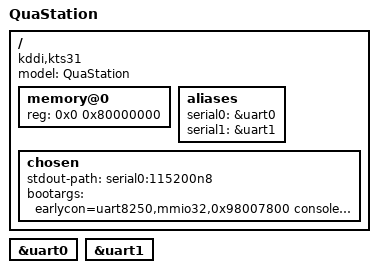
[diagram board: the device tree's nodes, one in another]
/*
 * Copyright (c) 2016-2017 Andreas Färber
 *
 * SPDX-License-Identifier: (GPL-2.0+ OR MIT)
 */

/dts-v1/;

#include "rtd1295.dtsi"

/ {
	compatible = "kddi,kts31", "realtek,rtd1295","Realtek,rtd1295";
	model = "QuaStation";

	memory@0 {
		device_type = "memory";
		reg = <0x0 0x80000000>;
	};

	aliases {
		serial0 = &uart0;
		serial1 = &uart1;
	};

	chosen {
		stdout-path = "serial0:115200n8";
		bootargs = "earlycon=uart8250,mmio32,0x98007800 console=ttyS0,115200";
	};
};

&uart0 {
	status = "okay";
};

&uart1 {
	status = "okay";
};
